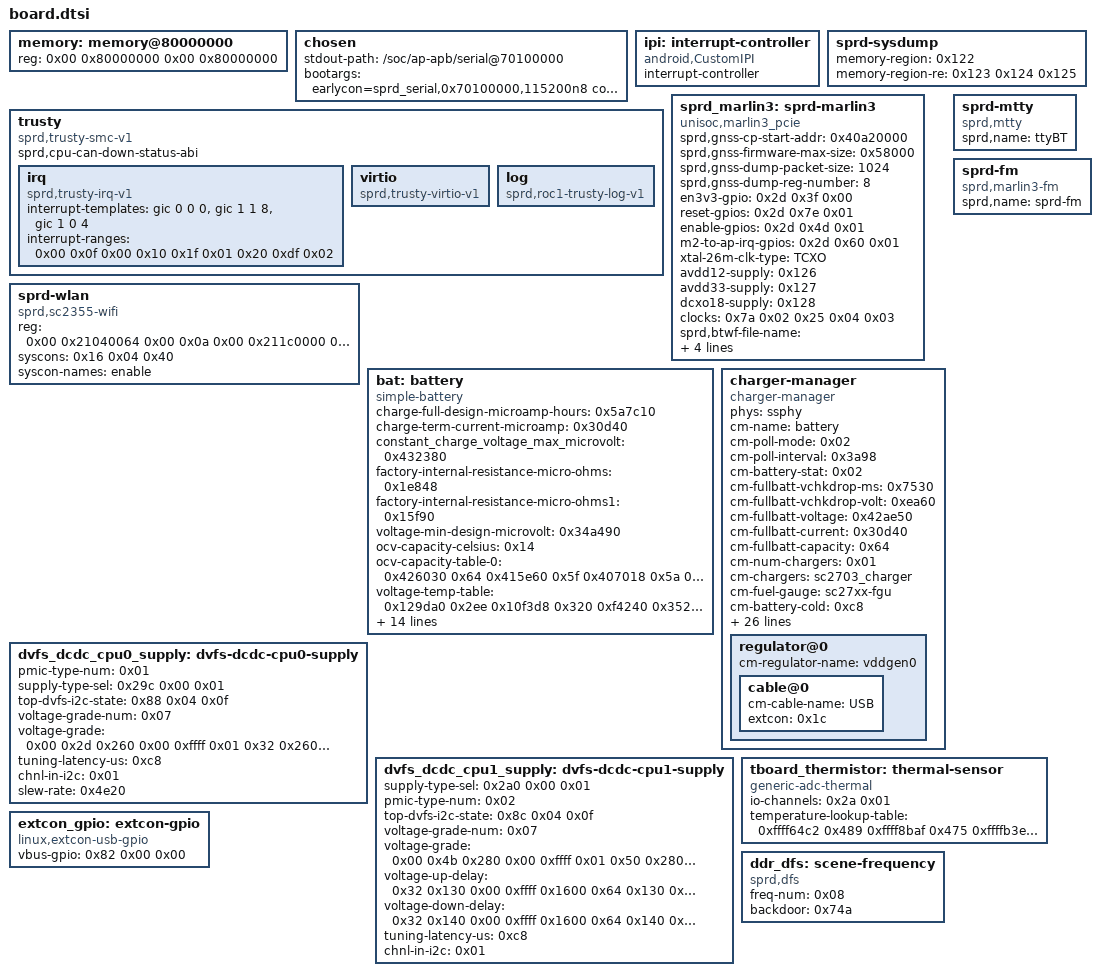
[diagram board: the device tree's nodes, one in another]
/*
 * istudy-c10 hardware description; included in place from the board DTS.
 * Copyright (C) 2026 Evarentha - Linux 5.15 board port changes.
 */

	memory: memory@80000000 {
		device_type = "memory";
		reg = <0x00 0x80000000 0x00 0x80000000>;
		phandle = <0x122>;
	};

	chosen {
		stdout-path = "/soc/ap-apb/serial@70100000";
		bootargs = "earlycon=sprd_serial,0x70100000,115200n8 console=ttyS1,115200n8 loglevel=1 no_console_suspend init=/init root=/dev/mmcblk0p30 rootfstype=ext4 ro rootwait androidboot.hardware=tx20 androidboot.dtbo_idx=0 pcie_ports=compat";
	};

	ipi: interrupt-controller {
		compatible = "android,CustomIPI";
		#interrupt-cells = <0x01>;
		interrupt-controller;
		phandle = <0x121>;
	};

	trusty {
		compatible = "sprd,trusty-smc-v1";
		sprd,cpu-can-down-status-abi;

		irq {
			compatible = "sprd,trusty-irq-v1";
			interrupt-templates = <&gic 0 0 0>, <&gic 1 1 8>, <&gic 1 0 4>;
			interrupt-ranges = <0x00 0x0f 0x00 0x10 0x1f 0x01 0x20 0xdf 0x02>;
		};

		virtio {
			compatible = "sprd,trusty-virtio-v1";
		};

		log {
			compatible = "sprd,roc1-trusty-log-v1";
		};
	};

	sprd-sysdump {
		memory-region = <0x122>;
		memory-region-re = <0x123 0x124 0x125>;
	};

	sprd_marlin3: sprd-marlin3 {
		compatible = "unisoc,marlin3_pcie";
		/* SC2355 addresses/sizes from the C10 4.14 WCN implementation. */
		sprd,gnss-cp-start-addr = <0x40a20000>;
		sprd,gnss-firmware-max-size = <0x58000>;
		sprd,gnss-dump-packet-size = <1024>;
		sprd,gnss-dump-reg-number = <8>;
		en3v3-gpio = <0x2d 0x3f 0x00>;
		reset-gpios = <0x2d 0x7e 0x01>;
		enable-gpios = <0x2d 0x4d 0x01>;
		m2-to-ap-irq-gpios = <0x2d 0x60 0x01>;
		xtal-26m-clk-type = "TCXO";
		avdd12-supply = <0x126>;
		avdd33-supply = <0x127>;
		dcxo18-supply = <0x128>;
		clock-names = "clk_32k", "source", "enable";
		clocks = <0x7a 0x02 0x25 0x04 0x03>;
		sprd,btwf-file-name = "/dev/block/platform/soc/soc:ap-apb/71400000.sdio/by-name/wcnmodem";
		sprd,gnss-file-name = "/dev/block/platform/soc/soc:ap-apb/71400000.sdio/by-name/gnssmodem";
		sprd,rc-ctrl = <0x129>;
		phandle = <0x1f0>;
	};

	sprd-wlan {
		compatible = "sprd,sc2355-wifi";
		reg = <0x00 0x21040064 0x00 0x0a 0x00 0x211c0000 0x00 0x3000>;
		reg-names = "wifi_ipaqos", "pam_wifi_reg_base_remap";
		syscons = <0x16 0x04 0x40>;
		syscon-names = "enable";
	};

	bat: battery {
		compatible = "simple-battery";
		charge-full-design-microamp-hours = <0x5a7c10>;
		charge-term-current-microamp = <0x30d40>;
		constant_charge_voltage_max_microvolt = <0x432380>;
		factory-internal-resistance-micro-ohms = <0x1e848>;
		factory-internal-resistance-micro-ohms1 = <0x15f90>;
		voltage-min-design-microvolt = <0x34a490>;
		ocv-capacity-celsius = <0x14>;
		ocv-capacity-table-0 = <0x426030 0x64 0x415e60 0x5f 0x407018 0x5a 0x3f8d88 0x55 0x3eb2c8 0x50 0x3def78 0x4b 0x3d0ce8 0x46 0x3c7878 0x41 0x3bcc98 0x3c 0x3b0178 0x37 0x3a8478 0x32 0x3a26b8 0x2d 0x39e450 0x28 0x39b570 0x23 0x399a18 0x1e 0x396b38 0x19 0x3928d0 0x14 0x38d2e0 0x0f 0x383a88 0x0a 0x36dee0 0x05 0x33e140 0x00>;
		voltage-temp-table = <0x129da0 0x2ee 0x10f3d8 0x320 0xf4240 0x352 0xd9878 0x384 0xbfe50 0x3b6 0xa7b98 0x3e8 0x91820 0x41a 0x7dbb8 0x44c 0x6c278 0x47e 0x5c878 0x4b0 0x4f588 0x4e2 0x43df0 0x514 0x39dc8 0x546 0x318f8 0x578 0x2a7b0 0x5aa 0x24608 0x5dc 0x1f7e8 0x60e 0x1b198 0x640 0x17700 0x672 0x14438 0x6a4>;
		capacity-temp-table = <0x2d 0x64 0x19 0x64 0x0a 0x64 0x00 0x59 0xfffffff6 0x55 0xffffffec 0x32>;
		resistance-temp-table = <0x2d 0x47 0x19 0x64 0x0a 0x8a 0x00 0x14c 0xfffffff6 0x165 0xffffffec 0x1de>;
		capacity-temp-table1 = <0x32 0x64 0x19 0x64 0x0a 0x64 0x00 0x60 0xfffffff6 0x53 0xffffffec 0x33>;
		resistance-temp-table1 = <0x32 0x50 0x19 0x64 0x0a 0xba 0x00 0x1a1 0xfffffff6 0x2e0 0xffffffec 0x481>;
		charge-sdp-current-microamp = <0x7a120 0x7a120>;
		charge-dcp-current-microamp = <0x1e8480 0x1e8480>;
		charge-cdp-current-microamp = <0x16e360 0x16e360>;
		charge-unknown-current-microamp = <0xf4240 0xf4240>;
		charge-fchg-current-microamp = <0x1e8480 0xf4240>;
		phandle = <0x84>;
	};

	charger-manager {
		compatible = "charger-manager";
		phys = <&ssphy>;
		cm-name = "battery";
		cm-poll-mode = <0x02>;
		cm-poll-interval = <0x3a98>;
		cm-battery-stat = <0x02>;
		cm-fullbatt-vchkdrop-ms = <0x7530>;
		cm-fullbatt-vchkdrop-volt = <0xea60>;
		cm-fullbatt-voltage = <0x42ae50>;
		cm-fullbatt-current = <0x30d40>;
		cm-fullbatt-capacity = <0x64>;
		cm-num-chargers = <0x01>;
		cm-chargers = "sc2703_charger";
		cm-fuel-gauge = "sc27xx-fgu";
		cm-battery-cold = <0xc8>;
		cm-battery-cold-in-minus;
		cm-battery-hot = <0x320>;
		cm-battery-temp-diff = <0x64>;
		cm-charging-max = <0x3dcc500>;
		cm-discharging-max = <0xa4cb80>;
		cm-wdt-interval = <0x3c>;
		cm-shutdown-voltage = <0x2f4d60>;
		cm-tickle-time-out = <0x12c>;
		cm-one-cap-time = <0x1e>;
		cm-charge-voltage-max = <0x632ea0>;
		cm-charge-voltage-drop = <0xaae60>;
		cm-fast-charge-voltage-max = <0xa037a0>;
		cm-fast-charge-voltage-drop = <0xaae60>;
		cm-fast-charge-all-current = <0x1e8480>;
		cm-dcp-jeita-temp-table = <0x3e8 0x406 0x00 0x432380 0x47e 0x49c 0x124f80 0x432380 0x5aa 0x58c 0x1e8480 0x432380 0x640 0x622 0x124f80 0x419ce0>;
		cm-sdp-jeita-temp-table = <0x3e8 0x406 0x00 0x432380 0x47e 0x49c 0x7a120 0x432380 0x5aa 0x58c 0x7a120 0x432380 0x640 0x622 0x7a120 0x419ce0>;
		cm-cdp-jeita-temp-table = <0x3e8 0x406 0x00 0x432380 0x47e 0x49c 0x7a120 0x432380 0x5aa 0x58c 0x16e360 0x432380 0x640 0x622 0x7a120 0x419ce0>;
		cm-unknown-jeita-temp-table = <0x3e8 0x406 0x00 0x432380 0x47e 0x49c 0xf4240 0x432380 0x5aa 0x58c 0xf4240 0x432380 0x640 0x622 0x7a120 0x419ce0>;
		cm-fchg-jeita-temp-table = <0x3e8 0x406 0x00 0x432380 0x47e 0x49c 0x927c0 0x432380 0x5aa 0x58c 0x1e8480 0x432380 0x640 0x622 0x927c0 0x419ce0>;
		monitored-battery = <0x84 0x84>;
		cm-capacity-track;

		regulator@0 {
			cm-regulator-name = "vddgen0";

			cable@0 {
				cm-cable-name = "USB";
				extcon = <0x1c>;
			};
		};
	};

	sprd-mtty {
		compatible = "sprd,mtty";
		sprd,name = "ttyBT";
	};

	sprd-fm {
		compatible = "sprd,marlin3-fm";
		sprd,name = "sprd-fm";
	};

	dvfs_dcdc_cpu0_supply: dvfs-dcdc-cpu0-supply {
		pmic-type-num = <0x01>;
		supply-type-sel = <0x29c 0x00 0x01>;
		top-dvfs-i2c-state = <0x88 0x04 0x0f>;
		voltage-grade-num = <0x07>;
		voltage-grade = <0x00 0x2d 0x260 0x00 0xffff 0x01 0x32 0x260 0x10 0xffff 0x02 0x37 0x264 0x00 0xffff 0x03 0x3c 0x264 0x10 0xffff 0x04 0x41 0x268 0x00 0xffff 0x05 0x46 0x268 0x10 0xffff 0x06 0x4b 0x26c 0x00 0xffff>;
		tuning-latency-us = <0xc8>;
		chnl-in-i2c = <0x01>;
		slew-rate = <0x4e20>;
		phandle = <0x57>;
	};

	dvfs_dcdc_cpu1_supply: dvfs-dcdc-cpu1-supply {
		supply-type-sel = <0x2a0 0x00 0x01>;
		pmic-type-num = <0x02>;
		top-dvfs-i2c-state = <0x8c 0x04 0x0f>;
		voltage-grade-num = <0x07>;
		voltage-grade = <0x00 0x4b 0x280 0x00 0xffff 0x01 0x50 0x280 0x10 0xffff 0x02 0x55 0x284 0x00 0xffff 0x03 0x5a 0x284 0x10 0xffff 0x04 0x5f 0x288 0x00 0xffff 0x05 0x64 0x288 0x10 0xffff 0x06 0x69 0x28c 0x00 0xffff>;
		voltage-up-delay = <0x32 0x130 0x00 0xffff 0x1600 0x64 0x130 0x10 0xffff 0x1a00 0x96 0x134 0x00 0xffff 0x1f00 0xc8 0x134 0x10 0xffff 0x2400 0xfa 0x138 0x00 0xffff 0x2900 0x12c 0x138 0x10 0xffff 0x2e00 0x15e 0x13c 0x00 0xffff 0x3300>;
		voltage-down-delay = <0x32 0x140 0x00 0xffff 0x1600 0x64 0x140 0x10 0xffff 0x1a00 0x96 0x144 0x00 0xffff 0x1f00 0xc8 0x144 0x10 0xffff 0x2400 0xfa 0x148 0x00 0xffff 0x2900 0x12c 0x148 0x10 0xffff 0x2e00 0x15e 0x14c 0x00 0xffff 0x3300>;
		tuning-latency-us = <0xc8>;
		chnl-in-i2c = <0x01>;
		phandle = <0x58>;
	};

	tboard_thermistor: thermal-sensor {
		compatible = "generic-adc-thermal";
		#thermal-sensor-cells = <0x00>;
		io-channels = <0x2a 0x01>;
		io-channel-names = "sensor-channel";
		temperature-lookup-table = <0xffff64c2 0x489 0xffff8baf 0x475 0xffffb3e8 0x451 0xffffedb9 0x3f4 0x277e 0x35f 0x60e5 0x2a0 0xaf7a 0x1a7 0xd677 0x143 0xfd7f 0xf3 0x12484 0xb6 0x14b93 0x88 0x172a3 0x66 0x199b0 0x4d 0x1c0c9 0x3a 0x1e7c8 0x2d>;
		phandle = <0x110>;
	};

	extcon_gpio: extcon-gpio {
		compatible = "linux,extcon-usb-gpio";
		vbus-gpio = <0x82 0x00 0x00>;
		phandle = <0x27>;
	};

	ddr_dfs: scene-frequency {
		compatible = "sprd,dfs";
		freq-num = <0x08>;
		backdoor = <0x74a>;
		phandle = <0x1f1>;
	};
